# STM32L07x register map
File version: 1.0
Registers are 32-bit, read-write, reset 0x0 unless marked. A register's access mark holds for its fields unless they carry their own. Offsets are from the block's base; [hi:lo] are bit positions; {n}, {i} and the like mark numbered series.

## ADC — Analog-to-digital converter
Base 0x40012400
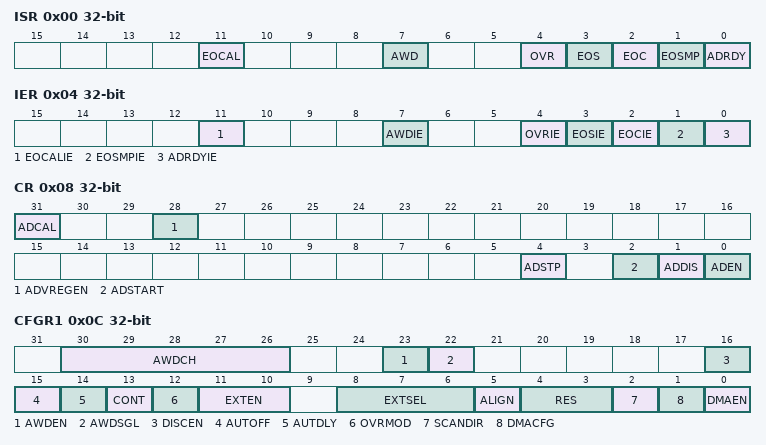
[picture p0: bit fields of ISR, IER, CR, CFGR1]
0x00 ISR — interrupt and status register
  [11] EOCAL — End Of Calibration flag
  [7] AWD — Analog watchdog flag
  [4] OVR — ADC overrun
  [3] EOS — End of sequence flag
  [2] EOC — End of conversion flag
  [1] EOSMP — End of sampling flag
  [0] ADRDY — ADC ready
0x04 IER — interrupt enable register
  [11] EOCALIE — End of calibration interrupt enable
  [7] AWDIE — Analog watchdog interrupt enable
  [4] OVRIE — Overrun interrupt enable
  [3] EOSIE — End of conversion sequence interrupt enable
  [2] EOCIE — End of conversion interrupt enable
  [1] EOSMPIE — End of sampling flag interrupt enable
  [0] ADRDYIE — ADC ready interrupt enable
0x08 CR — control register
  [31] ADCAL — ADC calibration
  [28] ADVREGEN — ADC Voltage Regulator Enable
  [4] ADSTP — ADC stop conversion command
  [2] ADSTART — ADC start conversion command
  [1] ADDIS — ADC disable command
  [0] ADEN — ADC enable command
0x0C CFGR1 — configuration register 1
  [30:26] AWDCH — Analog watchdog channel selection
  [23] AWDEN — Analog watchdog enable
  [22] AWDSGL — Enable the watchdog on a single channel or on all channels
  [16] DISCEN — Discontinuous mode
  [15] AUTOFF — Auto-off mode
  [14] AUTDLY — Auto-delayed conversion mode
  [13] CONT — Single / continuous conversion mode
  [12] OVRMOD — Overrun management mode
  [11:10] EXTEN — External trigger enable and polarity selection
  [8:6] EXTSEL — External trigger selection
  [5] ALIGN — Data alignment
  [4:3] RES — Data resolution
  [2] SCANDIR — Scan sequence direction
  [1] DMACFG — Direct memery access configuration
  [0] DMAEN — Direct memory access enable
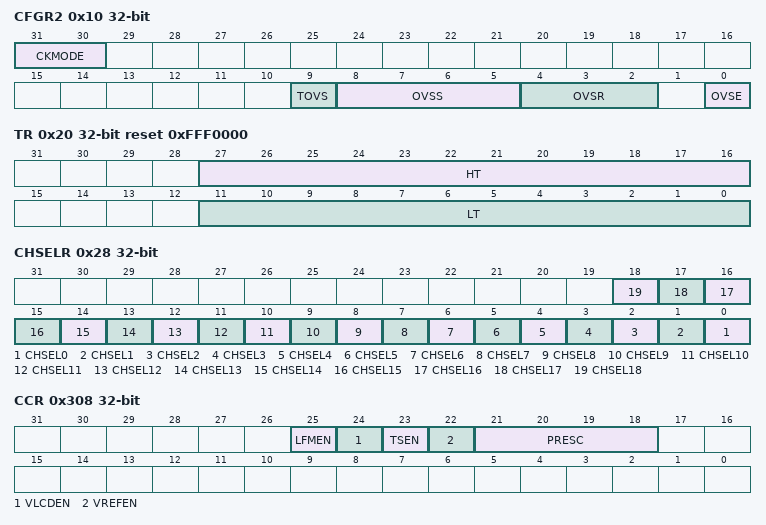
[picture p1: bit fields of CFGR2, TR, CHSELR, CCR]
0x10 CFGR2 — configuration register 2
  [31:30] CKMODE — ADC clock mode
  [9] TOVS — Triggered Oversampling
  [8:5] OVSS — Oversampling shift
  [4:2] OVSR — Oversampling ratio
  [0] OVSE — Oversampler Enable
0x14 SMPR — sampling time register
  [2:0] SMPR — Sampling time selection
0x20 TR reset 0xFFF0000 — watchdog threshold register
  [27:16] HT — Analog watchdog higher threshold
  [11:0] LT — Analog watchdog lower threshold
0x28 CHSELR — channel selection register
  [n] CHSEL{n} (n=0..18) — Channel-x selection
0x40 DR ro — data register
  [15:0] DATA — Converted data
0xB4 CALFACT — ADC Calibration factor
  [6:0] CALFACT — Calibration factor
0x308 CCR — ADC common configuration register
  [25] LFMEN — Low Frequency Mode enable
  [24] VLCDEN — VLCD enable
  [23] TSEN — Temperature sensor enable
  [22] VREFEN — VREFINT enable
  [21:18] PRESC — ADC prescaler

## DBGMCU — Debug support
Base 0x40015800
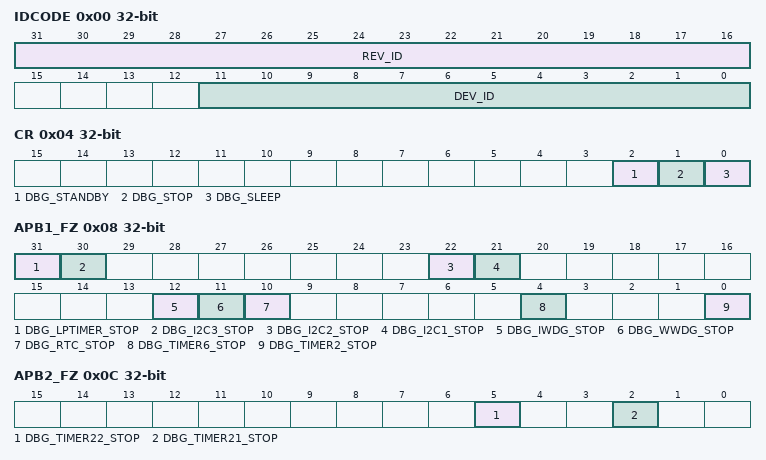
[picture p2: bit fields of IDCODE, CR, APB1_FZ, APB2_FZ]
0x00 IDCODE ro — MCU Device ID Code Register
  [31:16] REV_ID — Revision Identifier
  [11:0] DEV_ID — Device Identifier
0x04 CR — Debug MCU Configuration Register
  [2] DBG_STANDBY — Debug Standby Mode
  [1] DBG_STOP — Debug Stop Mode
  [0] DBG_SLEEP — Debug Sleep Mode
0x08 APB1_FZ — APB Low Freeze Register
  [31] DBG_LPTIMER_STOP — LPTIM1 counter stopped when core is halted
  [30] DBG_I2C3_STOP — I2C3 SMBUS timeout mode stopped when core is halted
  [22] DBG_I2C2_STOP — I2C2 SMBUS timeout mode stopped when core is halted
  [21] DBG_I2C1_STOP — I2C1 SMBUS timeout mode stopped when core is halted
  [12] DBG_IWDG_STOP — Debug Independent Wachdog stopped when Core is halted
  [11] DBG_WWDG_STOP — Debug Window Wachdog stopped when Core is halted
  [10] DBG_RTC_STOP — Debug RTC stopped when Core is halted
  [4] DBG_TIMER6_STOP — Debug Timer 6 stopped when Core is halted
  [0] DBG_TIMER2_STOP — Debug Timer 2 stopped when Core is halted
0x0C APB2_FZ — APB High Freeze Register
  [5] DBG_TIMER22_STOP — Debug Timer 22 stopped when Core is halted
  [2] DBG_TIMER21_STOP — Debug Timer 21 stopped when Core is halted

## TIM6 — Basic-timers
Base 0x40001000
Same registers: TIM7 0x40000C00
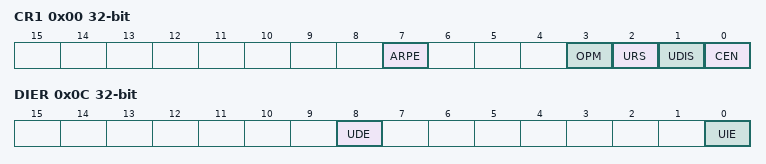
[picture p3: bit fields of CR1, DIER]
0x00 CR1 — control register 1
  [7] ARPE — Auto-reload preload enable
  [3] OPM — One-pulse mode
  [2] URS — Update request source
  [1] UDIS — Update disable
  [0] CEN — Counter enable
0x04 CR2 — control register 2
  [6:4] MMS — Master mode selection
0x0C DIER — DMA/Interrupt enable register
  [8] UDE — Update DMA request enable
  [0] UIE — Update interrupt enable
0x10 SR — status register
  [0] UIF — Update interrupt flag
0x14 EGR wo — event generation register
  [0] UG — Update generation
0x24 CNT — counter
  [15:0] CNT — Low counter value
0x28 PSC — prescaler
  [15:0] PSC — Prescaler value
0x2C ARR — auto-reload register
  [15:0] ARR — Low Auto-reload value
